# HT32F1655_56 register map
File version: 1.1
CPU: CM3 r2p0, little endian, no MPU, no FPU, 4 interrupt priority bits
Registers are 32-bit, read-write, reset 0x0 unless marked. A register's access mark holds for its fields unless they carry their own. Offsets are from the block's base; [hi:lo] are bit positions; {n}, {i} and the like mark numbered series.

## SCB
Base 0xE000ED10
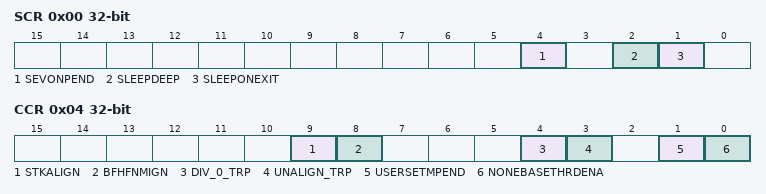
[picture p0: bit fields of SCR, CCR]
0x00 SCR
  [4] SEVONPEND, [2] SLEEPDEEP, [1] SLEEPONEXIT
0x04 CCR
  [9] STKALIGN, [8] BFHFNMIGN, [4] DIV_0_TRP, [3] UNALIGN_TRP, [1] USERSETMPEND, [0] NONEBASETHRDENA

## SysTick
Base 0xE000E010
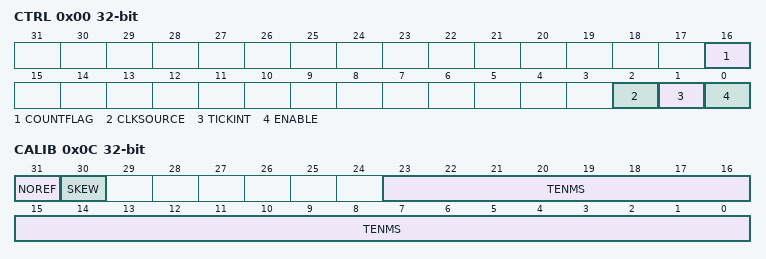
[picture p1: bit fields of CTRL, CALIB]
0x00 CTRL
  [16] COUNTFLAG, [2] CLKSOURCE, [1] TICKINT, [0] ENABLE
0x04 LOAD
  [23:0] RELOAD
0x08 VAL
  [23:0] CURRENT
0x0C CALIB
  [31] NOREF, [30] SKEW, [23:0] TENMS

## Fault_Reports
Base 0xE000ED28
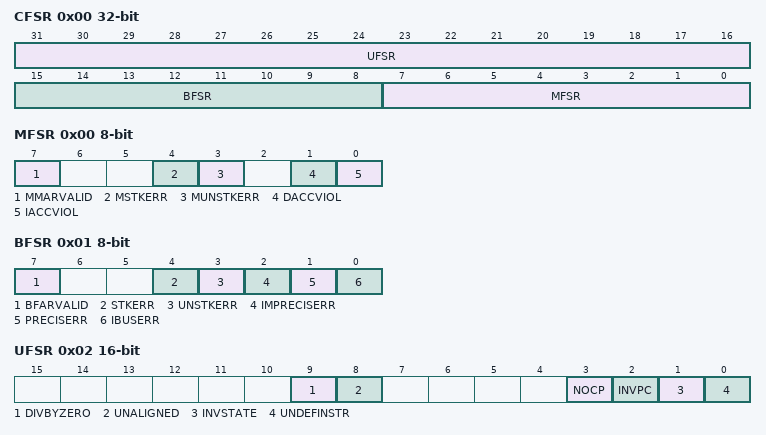
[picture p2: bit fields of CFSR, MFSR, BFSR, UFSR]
0x00 CFSR
  [31:16] UFSR, [15:8] BFSR, [7:0] MFSR
0x00 MFSR 8-bit (Fault_Reports view)
  [7] MMARVALID, [4] MSTKERR, [3] MUNSTKERR, [1] DACCVIOL, [0] IACCVIOL
0x01 BFSR 8-bit
  [7] BFARVALID, [4] STKERR, [3] UNSTKERR, [2] IMPRECISERR, [1] PRECISERR, [0] IBUSERR
0x02 UFSR 16-bit
  [9] DIVBYZERO, [8] UNALIGNED, [3] NOCP, [2] INVPC, [1] INVSTATE, [0] UNDEFINSTR
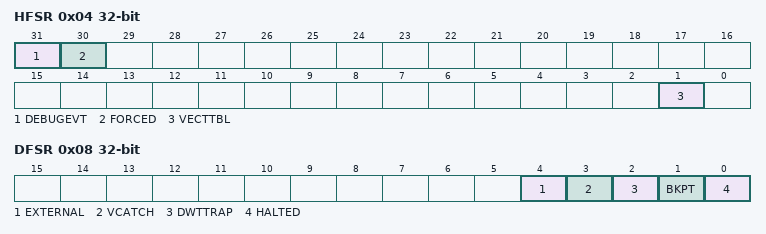
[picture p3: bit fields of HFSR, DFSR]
0x04 HFSR
  [31] DEBUGEVT, [30] FORCED, [1] VECTTBL
0x08 DFSR
  [4] EXTERNAL, [3] VCATCH, [2] DWTTRAP, [1] BKPT, [0] HALTED
0x0C MMFAR
  [31:0] ADDRESS
0x10 BFAR
  [31:0] ADDRESS
0x14 AFSR
  [31:0] IMPDEF

## FMC
Base 0x40080000
0x00 FMC_TADR
  [31:0] TADB
0x04 FMC_WRDR
  [31:0] WRDB
0x0C FMC_OCMR
  [3:0] CMD
0x10 FMC_OPCR
  [4:1] OPM
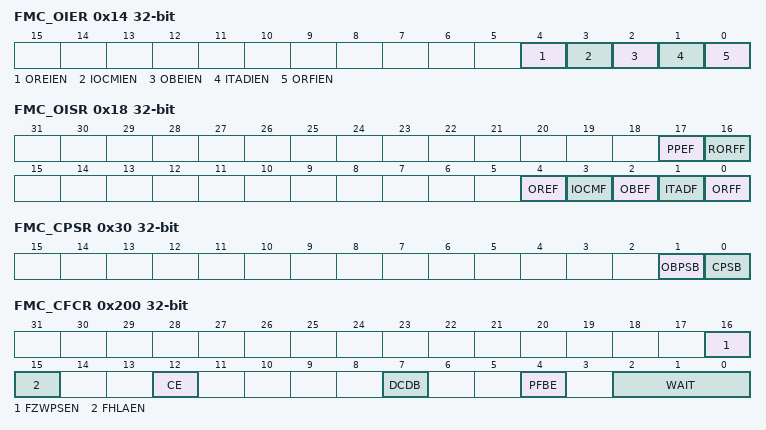
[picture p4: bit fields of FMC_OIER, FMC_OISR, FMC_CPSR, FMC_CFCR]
0x14 FMC_OIER
  [4] OREIEN, [3] IOCMIEN, [2] OBEIEN, [1] ITADIEN, [0] ORFIEN
0x18 FMC_OISR
  [17] PPEF, [16] RORFF, [4] OREF, [3] IOCMF, [2] OBEF, [1] ITADF, [0] ORFF
{0x20+4i} FMC_PPSR{i} (i=0..3)
  [31:0] PPSB
0x30 FMC_CPSR
  [1] OBPSB, [0] CPSB
0x100 FMC_VMCR
  [1:0] VMCB
0x200 FMC_CFCR
  [16] FZWPSEN, [15] FHLAEN, [12] CE, [7] DCDB, [4] PFBE, [2:0] WAIT
{0x300+4i} FMC_SBVT{i} (i=0..3)
  [31:0] SBVT

## PWRCU
Base 0x4006A100
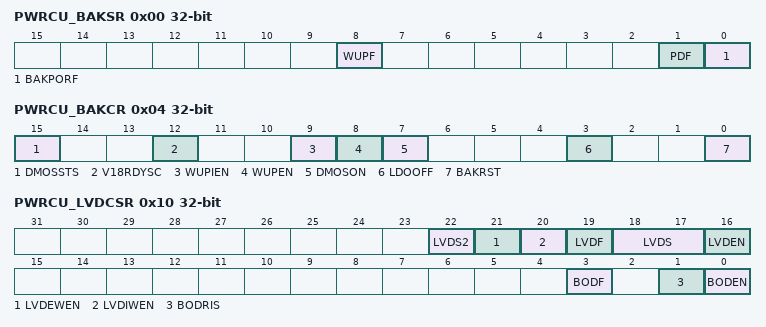
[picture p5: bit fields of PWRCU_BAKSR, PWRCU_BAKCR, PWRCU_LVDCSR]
0x00 PWRCU_BAKSR
  [8] WUPF, [1] PDF, [0] BAKPORF
0x04 PWRCU_BAKCR
  [15] DMOSSTS, [12] V18RDYSC, [9] WUPIEN, [8] WUPEN, [7] DMOSON, [3] LDOOFF, [0] BAKRST
0x08 PWRCU_BAKTEST
  [7:0] BAKTEST
0x0C PWRCU_HSIRCR
  [1:0] HSIRCBL
0x10 PWRCU_LVDCSR
  [22] LVDS2 — LVDEWEN
  [21] LVDEWEN
  [20] LVDIWEN
  [19] LVDF
  [18:17] LVDS
  [16] LVDEN
  [3] BODF
  [1] BODRIS
  [0] BODEN
{0x100+4i} PWRCU_BAKREG{i} (i=0..9)
  [31:0] BAKREG

## CKCU
Base 0x40088000
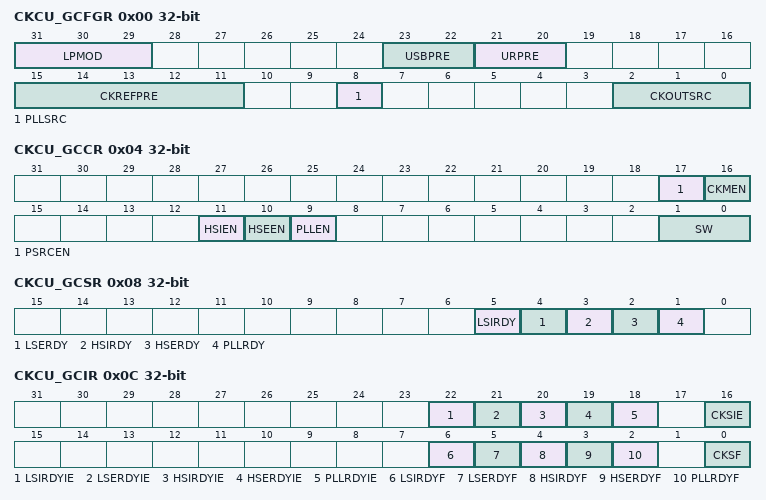
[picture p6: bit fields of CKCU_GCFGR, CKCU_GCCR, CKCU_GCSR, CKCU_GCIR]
0x00 CKCU_GCFGR
  [31:29] LPMOD, [23:22] USBPRE, [21:20] URPRE, [15:11] CKREFPRE, [8] PLLSRC, [2:0] CKOUTSRC
0x04 CKCU_GCCR
  [17] PSRCEN, [16] CKMEN, [11] HSIEN, [10] HSEEN, [9] PLLEN, [1:0] SW
0x08 CKCU_GCSR
  [5] LSIRDY, [4] LSERDY, [3] HSIRDY, [2] HSERDY, [1] PLLRDY
0x0C CKCU_GCIR
  [22] LSIRDYIE, [21] LSERDYIE, [20] HSIRDYIE, [19] HSERDYIE, [18] PLLRDYIE, [16] CKSIE, [6] LSIRDYF, [5] LSERDYF, [4] HSIRDYF, [3] HSERDYF, [2] PLLRDYF, [0] CKSF
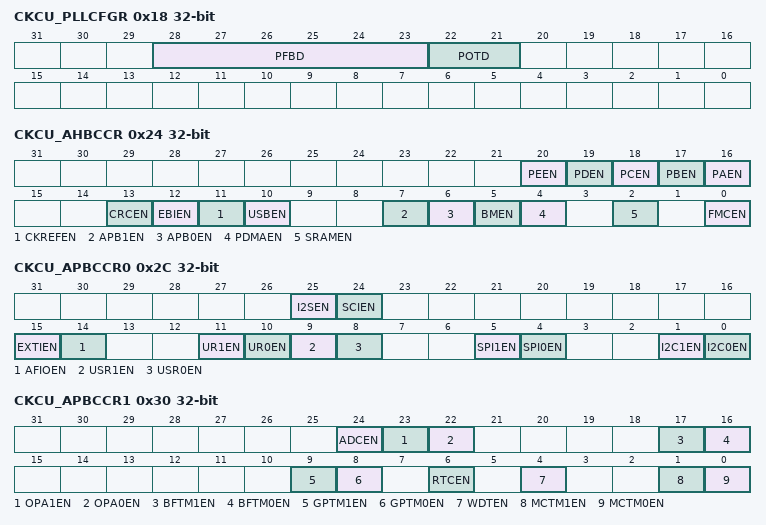
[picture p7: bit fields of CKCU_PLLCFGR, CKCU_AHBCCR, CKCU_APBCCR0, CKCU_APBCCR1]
0x18 CKCU_PLLCFGR
  [28:23] PFBD, [22:21] POTD
0x1C CKCU_PLLCR
  [31] PLLBPS
0x20 CKCU_AHBCFGR
  [1:0] AHBPRE
0x24 CKCU_AHBCCR
  [20] PEEN, [19] PDEN, [18] PCEN, [17] PBEN, [16] PAEN, [13] CRCEN, [12] EBIEN, [11] CKREFEN, [10] USBEN, [7] APB1EN, [6] APB0EN, [5] BMEN, [4] PDMAEN, [2] SRAMEN, [0] FMCEN
0x28 CKCU_APBCFGR
  [18:16] ADCDIV
0x2C CKCU_APBCCR0
  [25] I2SEN, [24] SCIEN, [15] EXTIEN, [14] AFIOEN, [11] UR1EN, [10] UR0EN, [9] USR1EN, [8] USR0EN, [5] SPI1EN, [4] SPI0EN, [1] I2C1EN, [0] I2C0EN
0x30 CKCU_APBCCR1
  [24] ADCEN, [23] OPA1EN, [22] OPA0EN, [17] BFTM1EN, [16] BFTM0EN, [9] GPTM1EN, [8] GPTM0EN, [6] RTCEN, [4] WDTEN, [1] MCTM1EN, [0] MCTM0EN
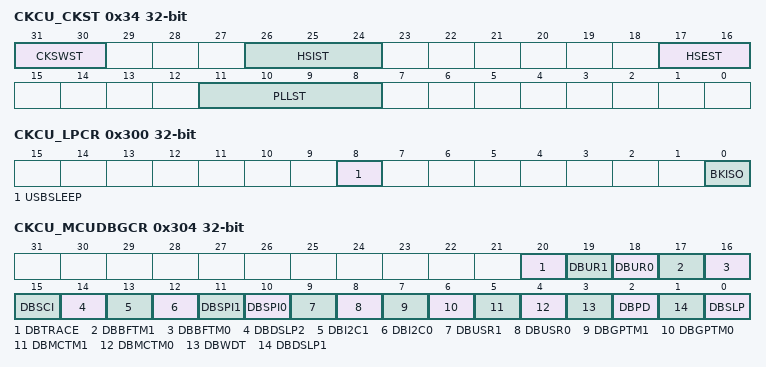
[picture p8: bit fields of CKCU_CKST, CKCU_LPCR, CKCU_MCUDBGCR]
0x34 CKCU_CKST
  [31:30] CKSWST, [26:24] HSIST, [17:16] HSEST, [11:8] PLLST
0x300 CKCU_LPCR
  [8] USBSLEEP, [0] BKISO
0x304 CKCU_MCUDBGCR
  [20] DBTRACE, [19] DBUR1, [18] DBUR0, [17] DBBFTM1, [16] DBBFTM0, [15] DBSCI, [14] DBDSLP2, [13] DBI2C1, [12] DBI2C0, [11] DBSPI1, [10] DBSPI0, [9] DBUSR1, [8] DBUSR0, [7] DBGPTM1, [6] DBGPTM0, [5] DBMCTM1, [4] DBMCTM0, [3] DBWDT, [2] DBPD, [1] DBDSLP1, [0] DBSLP

## RSTCU
Base 0x40088100
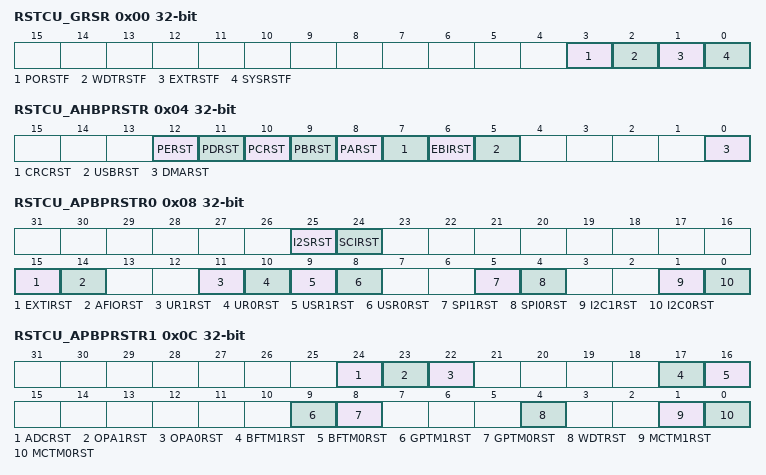
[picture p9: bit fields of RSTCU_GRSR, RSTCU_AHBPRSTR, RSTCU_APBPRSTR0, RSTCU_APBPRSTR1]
0x00 RSTCU_GRSR
  [3] PORSTF, [2] WDTRSTF, [1] EXTRSTF, [0] SYSRSTF
0x04 RSTCU_AHBPRSTR
  [12] PERST, [11] PDRST, [10] PCRST, [9] PBRST, [8] PARST, [7] CRCRST, [6] EBIRST, [5] USBRST, [0] DMARST
0x08 RSTCU_APBPRSTR0
  [25] I2SRST, [24] SCIRST, [15] EXTIRST, [14] AFIORST, [11] UR1RST, [10] UR0RST, [9] USR1RST, [8] USR0RST, [5] SPI1RST, [4] SPI0RST, [1] I2C1RST, [0] I2C0RST
0x0C RSTCU_APBPRSTR1
  [24] ADCRST, [23] OPA1RST, [22] OPA0RST, [17] BFTM1RST, [16] BFTM0RST, [9] GPTM1RST, [8] GPTM0RST, [4] WDTRST, [1] MCTM1RST, [0] MCTM0RST
